# STM32WBA20xx register map
File version: 1.0
Registers are 32-bit, read-write, reset 0x0 unless marked. A register's access mark holds for its fields unless they carry their own. Offsets are from the block's base; [hi:lo] are bit positions; {n}, {i} and the like mark numbered series.

## SYSCFG — System configuration controller
Base 0x46000400
0x00 SECCFGR — SYSCFG secure configuration register
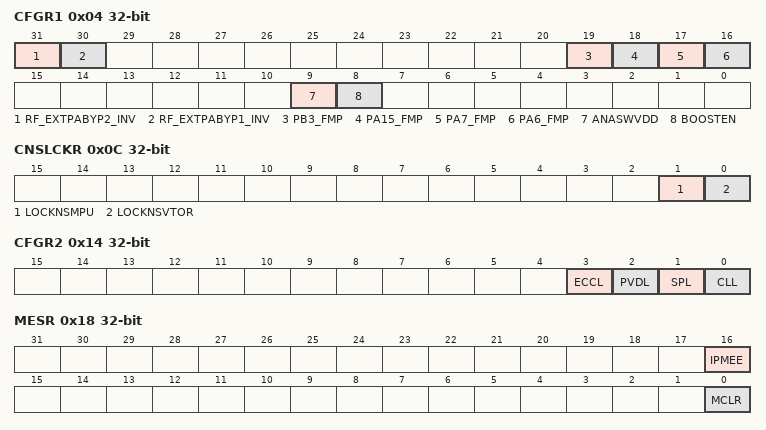
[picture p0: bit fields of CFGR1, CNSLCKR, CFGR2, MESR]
0x04 CFGR1 — SYSCFG configuration register 1
  [31] RF_EXTPABYP2_INV — signal RF_EXTPABYP2 inversion selection
  [30] RF_EXTPABYP1_INV — signal RF_EXTPABYP1 inversion selection
  [19] PB3_FMP — I2C PB3 Fast mode plus
  [18] PA15_FMP — I2C PA15 Fast mode plus
  [17] PA7_FMP — I2C PA7 Fast mode plus
  [16] PA6_FMP — I2C PA6 Fast mode plus
  [9] ANASWVDD — GPIO analog switch control voltage selection
  [8] BOOSTEN — I/O analog switch voltage booster enable
0x08 FPUIMR — SYSCFG FPU interrupt mask register
  [5:0] FPU_IE — All FPU interrupts enable
0x0C CNSLCKR — SYSCFG CPU non-secure lock register
  [1] LOCKNSMPU — Disable Non-Secure MPU registers writes by SW or debug agent
  [0] LOCKNSVTOR — Disable VTOR_NS register writes by SW or debug agent
0x10 CSLCKR — SYSCFG CPU secure lock register
0x14 CFGR2 — SYSCFG configuration register 2
  [3] ECCL — ECC Lock
  [2] PVDL — PVD Lock
  [1] SPL — SRAM Parity Lock
  [0] CLL — Core Lockup Lock
0x18 MESR — SYSCFG Memory Erase Status register
  [16] IPMEE — Status of End of Erase for ICache and PKA RAMs
  [0] MCLR — Status of Erase after Reset
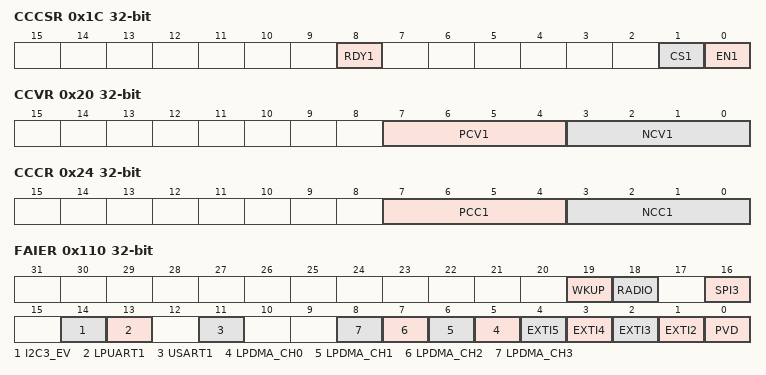
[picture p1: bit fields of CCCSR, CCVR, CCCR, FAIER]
0x1C CCCSR — SYSCFG Conpensation Cell Control&Status register
  [8] RDY1 — VDD compensation cell ready flag
  [1] CS1 — Code selection for VDD power rail
  [0] EN1 — Enable compensation cell for VDD power rail
0x20 CCVR — SYSCFG Conpensation Cell value register
  [7:4] PCV1 — PMOS compensation value for VDD Power Rail
  [3:0] NCV1 — NMOS compensation value for VDD Power Rail
0x24 CCCR — SYSCFG Conpensation Cell Code register
  [7:4] PCC1 — PMOS compensation code for VDD Power Rail
  [3:0] NCC1 — NMOS compensation code for VDD Power Rail
0x2C RSSCMDR — SYSCFG RSS command mode register
0x110 FAIER — SYSCFG flash abort interrupt enable register
  [19] WKUP — enable PWR WKUP interrupt to abort Flash operation
  [18] RADIO — enable RADIO interrupt to abort Flash operation
  [16] SPI3 — enable SPI3 interrupt to abort Flash operation
  [14] I2C3_EV — enable I2C3_EV interrupt to abort Flash operation
  [13] LPUART1 — enable LPUART1 interrupt to abort Flash operation
  [11] USART1 — enable USART1 interrupt to abort Flash operation
  [n+5] LPDMA_CH{n} (n=0..3) — enable LPDMA_CH{n} interrupt to abort Flash operation
  [n-1] EXTI{n} (n=2..5) — enable EXTI{n} interrupt to abort Flash operation
  [0] PVD — enable EXTI16 PVD interrupt to abort Flash operation

## TAMP — Tamper and backup registers
Base 0x46007C00
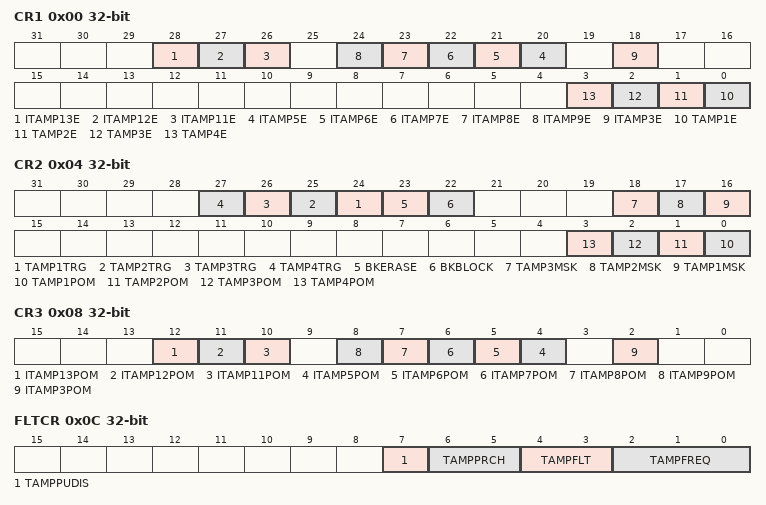
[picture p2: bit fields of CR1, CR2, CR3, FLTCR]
0x00 CR1 — TAMP configuration register 1
  [28] ITAMP13E, [27] ITAMP12E, [26] ITAMP11E, [n+15] ITAMP{n}E (n=5..9), [18] ITAMP3E, [n-1] TAMP{n}E (n=1..4)
0x04 CR2 — TAMP configuration register 2
  [n+23] TAMP{n}TRG (n=1..4), [23] BKERASE, [22] BKBLOCK, [18] TAMP3MSK, [17] TAMP2MSK, [16] TAMP1MSK, [n-1] TAMP{n}POM (n=1..4)
0x08 CR3 — TAMP configuration register 3
  [12] ITAMP13POM, [11] ITAMP12POM, [10] ITAMP11POM, [n-1] ITAMP{n}POM (n=5..9), [2] ITAMP3POM
0x0C FLTCR — TAMP filter control register
  [7] TAMPPUDIS
  [6:5] TAMPPRCH
    0=DURATION_1RTCCLK (Tamper pins are pre-charged before sampling during 1 RTCCLK cycle); 1=DURATION_2RTCCLK (Tamper pins are pre-charged before sampling during 2 RTCCLK cycles); 2=DURATION_4RTCCLK (Tamper pins are pre-charged before sampling during 4 RTCCLK cycles); 3=DURATION_8RTCCLK (Tamper pins are pre-charged before sampling during 8 RTCCLK cycles)
  [4:3] TAMPFLT
    0=DISABLE (Tamper filter is disabled); 1=FILTER_2SAMPLE (Tamper is activated after 2 consecutive samples at the active level); 2=FILTER_4SAMPLE (Tamper is activated after 4 consecutive samples at the active level); 3=FILTER_8SAMPLE (Tamper is activated after 8 consecutive samples at the active level)
  [2:0] TAMPFREQ
    0=SAMPLFREQDIV_32768 (Each of the tamper inputs are sampled with a frequency = RTCCLK / 32768); 1=SAMPLFREQDIV_16384 (Each of the tamper inputs are sampled with a frequency = RTCCLK / 16384); 2=SAMPLFREQDIV_8192 (Each of the tamper inputs are sampled with a frequency = RTCCLK / 8192); 3=SAMPLFREQDIV_4096 (Each of the tamper inputs are sampled with a frequency = RTCCLK / 4096); 4=SAMPLFREQDIV_2048 (Each of the tamper inputs are sampled with a frequency = RTCCLK / 2048); 5=SAMPLFREQDIV_1024 (Each of the tamper inputs are sampled with a frequency = RTCCLK / 1024); 6=SAMPLFREQDIV_512 (Each of the tamper inputs are sampled with a frequency = RTCCLK / 512); 7=SAMPLFREQDIV_256 (Each of the tamper inputs are sampled with a frequency = RTCCLK / 256)
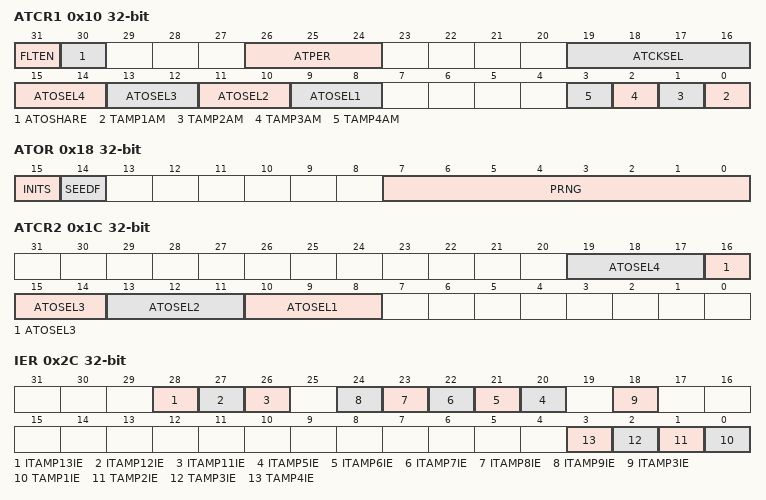
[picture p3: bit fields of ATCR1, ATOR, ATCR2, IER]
0x10 ATCR1 — TAMP filter control register 1
  [31] FLTEN
  [30] ATOSHARE
  [26:24] ATPER
  [19:16] ATCKSEL
  [15:14] ATOSEL4 — ATOSEL4[1:0] bits (Active tamper shared output 4 selection)
  [13:12] ATOSEL3
  [11:10] ATOSEL2
  [9:8] ATOSEL1
  [n-1] TAMP{n}AM (n=1..4)
0x14 ATSEEDR — TAMP active tamper seed register
  [31:0] SEED
0x18 ATOR — TAMP active tamper output register
  [15] INITS, [14] SEEDF, [7:0] PRNG
0x1C ATCR2 — TAMP filter control register 2
  [3n+7:3n+5] ATOSEL{n} (n=1..4)
0x2C IER — TAMP interrupt enable register
  [28] ITAMP13IE, [27] ITAMP12IE, [26] ITAMP11IE, [n+15] ITAMP{n}IE (n=5..9), [18] ITAMP3IE, [n-1] TAMP{n}IE (n=1..4)
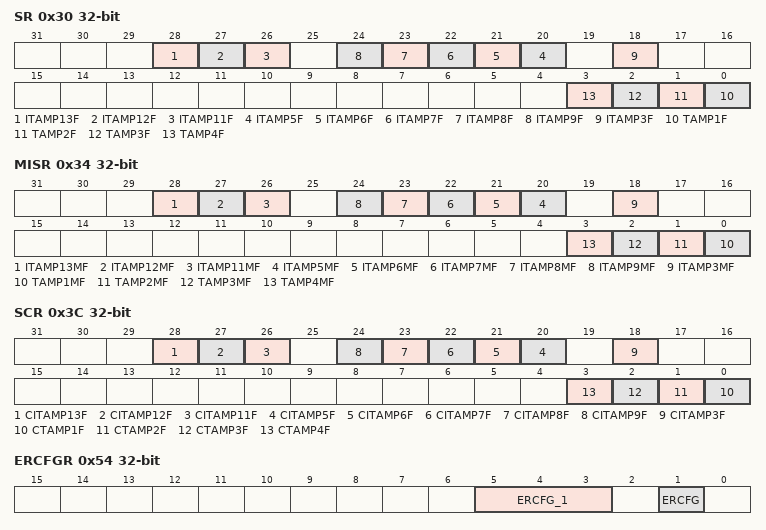
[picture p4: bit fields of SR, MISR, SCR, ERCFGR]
0x30 SR — TAMP status register
  [28] ITAMP13F, [27] ITAMP12F, [26] ITAMP11F, [n+15] ITAMP{n}F (n=5..9), [18] ITAMP3F, [n-1] TAMP{n}F (n=1..4)
0x34 MISR — TAMP masked interrupt status register
  [28] ITAMP13MF, [27] ITAMP12MF, [26] ITAMP11MF, [n+15] ITAMP{n}MF (n=5..9), [18] ITAMP3MF, [n-1] TAMP{n}MF (n=1..4)
0x3C SCR — TAMP status clear register
  [28] CITAMP13F, [27] CITAMP12F, [26] CITAMP11F, [n+15] CITAMP{n}F (n=5..9), [18] CITAMP3F, [n-1] CTAMP{n}F (n=1..4)
0x40 COUNT1R — TAMP monotonic counter 1 register
  [31:0] COUNT
0x54 ERCFGR — TAMP erase configuration register
  [5:3] ERCFG_1 — ERCFG (Configurable device secrets configuration)
  [1] ERCFG — ERCFG (Configurable device secrets configuration)
{0x100+4i} BKP{i}R (i=0..31) — TAMP backup register {i}
